# GAP8 register map
Vendor: GreenWaves Technologies SAS; Series: GAP8; File version: 1.3.1
CPU: other r1p0, little endian, MPU, no FPU, I-cache, DTCM, false interrupt priority bits
Registers are 32-bit, read-write, reset 0x0 unless marked. A register's access mark holds for its fields unless they carry their own. Offsets are from the block's base; [hi:lo] are bit positions; 'fields as' and 'values as' point back to an identical list.

## memcpy — uDMA MEMCPY interface
Base 0x1A102380
0x00 rx_saddr — uDMA RX MEMCPY buffer base address configuration register.
  [15:0] rx_saddr — RX buffer base address bitfield: - Read: returns value of the buffer pointer until transfer is finished. Else returns 0. - Write: sets RX buffer base address
0x04 rx_size — uDMA RX MEMCPY buffer size configuration register.
  [16:0] rx_size — RX buffer size bitfield in bytes. (128kBytes maximum) - Read: returns remaining buffer size to transfer. - Write: sets buffer size.
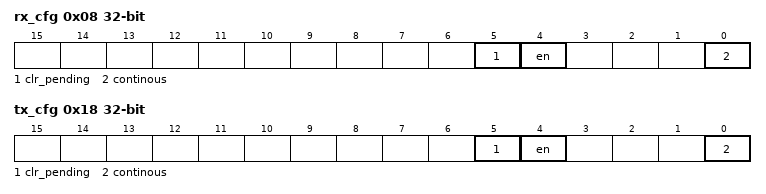
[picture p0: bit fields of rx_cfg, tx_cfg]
0x08 rx_cfg — uDMA RX MEMCPY stream configuration register.
  [5] clr_pending — RX channel clear and stop transfer RX transfer pending in queue status flag
    on write: 0=disable (feature is disabled); 1=stop and clear the on-going transfer | on read: 0=no pending transfer in the queue; 1=pending transfer in the queue
  [4] en — RX channel enable and start transfer bitfield This signal is used also to queue a transfer if one is already ongoing.
    0=disable (feature is disabled); 1=start (enable and start the transfer)
  [0] continous — RX channel continuous mode bitfield At the end of the buffer transfer, the uDMA reloads the address / buffer size and starts a new transfer.
    0=disabled (feature is disabled); 1=enabled (feature is enabled)
0x10 tx_saddr — uDMA TX MEMCPY buffer base address configuration register.
  [15:0] tx_saddr — TX buffer base address bitfield: - Read: returns value of the buffer pointer until transfer is finished. Else returns 0. - Write: sets buffer base address
0x14 tx_size — uDMA TX MEMCPY buffer size configuration register.
  [16:0] tx_size — TX buffer size bitfield in bytes. (128kBytes maximum) - Read: returns remaining buffer size to transfer. - Write: sets buffer size.
0x18 tx_cfg — uDMA TX MEMCPY stream configuration register.
  [5] clr_pending — TX channel clear and stop transfer bitfield TX transfer pending in queue status flag
    on write: 0=disabled (feature is disabled); 1=stop and clear the on-going transfer | on read: 0=no pending transfer in the queue; 1=pending transfer in the queue
  [4] en — TX channel enable and start transfer bitfield This signal is used also to queue a transfer if one is already ongoing.
    0=disabled (feature is disabled); 1=start (enable and start the transfer)
  [0] continous — TX channel continuous mode bitfield At the end of the buffer transfer, the uDMA reloads the address / buffer size and starts a new transfer.
    values as rx_cfg.continous
0x20 dst_addr — MEMCPY TX destination address configuration register.
  [16:0] dst_addr — TX destination start address configuration bitfield. MEMCPY TX transfer copy data from L2 TX_CFG.TX_SADDR address to FC_TCDM or L2 memories DST_ADDR address.
0x24 src_addr — MEMCPY RX source address configuration register.
  [16:0] src_addr — RX source start address configuration bitfield. MEMCPY RX transfer copy data from FC_TCDM or L2 memories SRC_ADDR address to L2 RX_CFG.RX_SADDR address.
0x28 mem_sel — MEMCPY memory source/destination select configuration register.
  [0] mem_sel — Memory selection configuration bitfield
    0=l2_from/to_fc_tcdm (set to L2 from/to FC_TCDM); 1=l2_from/to_l2 (set to L2 from/to L2)

## cpi — uDMA CPI interface
Base 0x1A102480
0x00 rx_saddr — uDMA RX CPI buffer base address configuration register.
  [15:0] rx_saddr — RX buffer base address bitfield: - Read: returns value of the buffer pointer until transfer is finished. Else returns 0. - Write: sets RX buffer base address
0x04 rx_size — uDMA RX CPI buffer size configuration register.
  [16:0] rx_size — RX buffer size bitfield in bytes. (128kBytes maximum) - Read: returns remaining buffer size to transfer. - Write: sets buffer size.
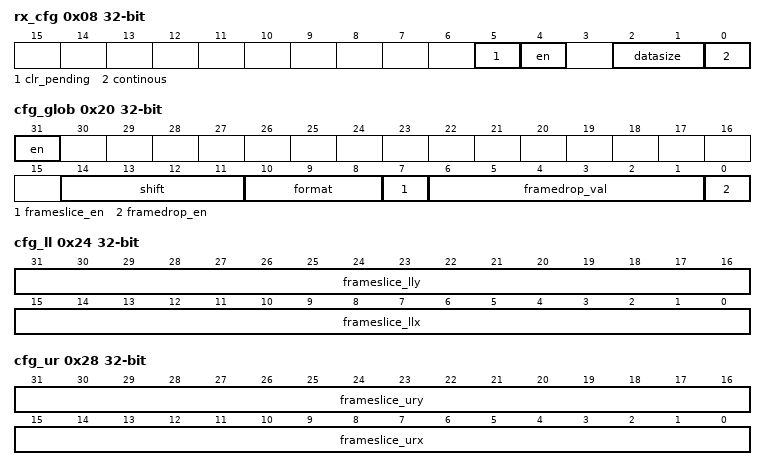
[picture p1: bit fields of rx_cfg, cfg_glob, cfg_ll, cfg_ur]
0x08 rx_cfg — uDMA RX CPI stream configuration register.
  [5] clr_pending — RX Channel clear and stop transfer RX Transfer pending in queue status flag
    on write: 0=disable (feature is disabled); 1=stop and clear – stop and clear the on-going transfer | on read: 0=no pending transfer in the queue; 1=pending transfer in the queue
  [4] en — RX Channel enable and start transfer bitfield This signal is used also to queue a transfer if one is already ongoing.
    0=disable (feature is disabled); 1=start – enable and start the transfer
  [2:1] datasize — RX channel transfer size used to increment uDMA CPI RX buffer address pointer
    0=plus_1 (+1 (8 bits)); 1=plus_2 (+2 (16 bits)); 2=plus_4 (+4 (32 bits)); 3=plus_0 (+0)
  [0] continous — RX channel continuous mode bitfield At the end of the buffer transfer, the uDMA reloads the address / buffer size and starts a new transfer.
    0=disabled (feature is disabled); 1=enabled (feature is enabled)
0x20 cfg_glob — uDMA CPI Global configuration register.
  [31] en — CPI interface acquisition enable bitfield The enable/disable happens only at the beginning of a frame, meaning when VSYNC pulse occurs.
    values as rx_cfg.continous
  [14:11] shift — Right shift value for final pixel normalisation bitfield. Not used if CFG_GLOB.FORMAT = BYPASS
  [10:8] format — Input frame format bitfield - 3’b101: BYPASS_BIGEND
    0=rgb565 (set to RGB565); 1=rgb555 (set to RGB555); 2=rgb444 (set to RGB444); 4=bypass_litend (set to BYPASS_LITEND)
  [7] frameslice_en — Input frame slicing bitfield
    values as rx_cfg.continous
  [6:1] framedrop_val — Frame dropping value bitfield.
  [0] framedrop_en — Frame dropping bitfield
    values as rx_cfg.continous
0x24 cfg_ll — uDMA CPI Lower Left corner configuration register.
  [31:16] frameslice_lly — Y coordinate of lower left corner of slice bitfield. Origin reference of a frame is left up corner.
  [15:0] frameslice_llx — X coordinate of lower left corner of slice bitfield. Origin reference of a frame is left up corner.
0x28 cfg_ur — uDMA CPI Upper Right corner configuration register.
  [31:16] frameslice_ury — Y coordinate of upper right corner of slice bitfield. Origin reference of a frame is left up corner.
  [15:0] frameslice_urx — X coordinate of upper right corner of slice bitfield. Origin reference of a frame is left up corner.
0x2C cfg_size — uDMA CPI Horizontal Resolution configuration register.
  [31:16] rowlen — Frame horizontal pixel length bitfield. It is used for slice mode. Value set into the bitfield must be equal to (rowlen - 1).
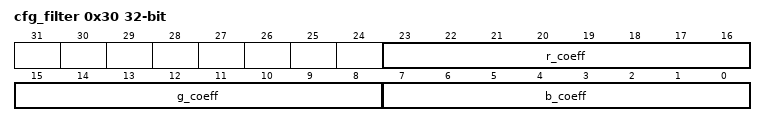
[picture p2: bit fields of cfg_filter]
0x30 cfg_filter — uDMA CPI RGB coefficients configuration register.
  [23:16] r_coeff — R component coefficient bitfield. Not used if CFG_GLOB.FORMAT = BYPASS.
  [15:8] g_coeff — G component coefficient bitfield.Not used if CFG_GLOB.FORMAT = BYPASS.
  [7:0] b_coeff — B component coefficient bitfield. Not used if CFG_GLOB.FORMAT = BYPASS.
